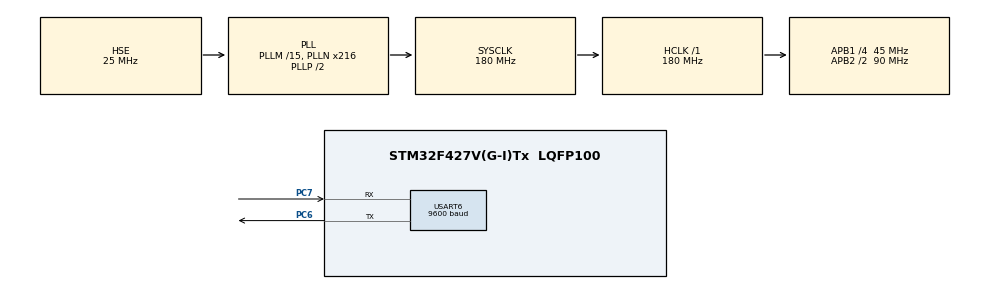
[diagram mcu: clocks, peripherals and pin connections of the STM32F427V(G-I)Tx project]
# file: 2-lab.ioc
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Mcu.Family=STM32F4
Mcu.Name=STM32F427V(G-I)Tx
Mcu.Package=LQFP100
NVIC.PriorityGroup=NVIC_PRIORITYGROUP_4
NVIC.USART6_IRQn=true\:0\:0\:false\:false\:true\:true\:true\:true
PA13.Mode=JTAG_5_pins
PA13.Signal=SYS_JTMS-SWDIO
PA14.Mode=JTAG_5_pins
PA14.Signal=SYS_JTCK-SWCLK
PA15.Mode=JTAG_5_pins
PA15.Signal=SYS_JTDI
PB3.Mode=JTAG_5_pins
PB3.Signal=SYS_JTDO-SWO
PB4.Mode=JTAG_5_pins
PB4.Signal=SYS_JTRST
PC6.Mode=Asynchronous
PC6.Signal=USART6_TX
PC7.Mode=Asynchronous
PC7.Signal=USART6_RX
PH0/OSC_IN.Mode=HSE-External-Oscillator
PH0/OSC_IN.Signal=RCC_OSC_IN
PH1/OSC_OUT.Mode=HSE-External-Oscillator
PH1/OSC_OUT.Signal=RCC_OSC_OUT
ProjectManager.HeapSize=0x200
ProjectManager.StackSize=0x400
ProjectManager.TargetToolchain=STM32CubeIDE
RCC.48MHZClocksFreq_Value=90000000
RCC.AHBFreq_Value=180000000
RCC.APB1CLKDivider=RCC_HCLK_DIV4
RCC.APB1Freq_Value=45000000
RCC.APB1TimFreq_Value=90000000
RCC.APB2CLKDivider=RCC_HCLK_DIV2
RCC.APB2Freq_Value=90000000
RCC.APB2TimFreq_Value=180000000
RCC.CortexFreq_Value=180000000
RCC.HCLKFreq_Value=180000000
RCC.HSE_VALUE=25000000
RCC.HSI_VALUE=16000000
RCC.LSE_VALUE=32768
RCC.PLLM=15
RCC.PLLN=216
RCC.PLLSourceVirtual=RCC_PLLSOURCE_HSE
RCC.SYSCLKFreq_VALUE=180000000
RCC.SYSCLKSource=RCC_SYSCLKSOURCE_PLLCLK
RCC.VCOOutputFreq_Value=360000000
USART6.BaudRate=9600
USART6.VirtualMode=VM_ASYNC
board=custom

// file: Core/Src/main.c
/* USER CODE BEGIN Header */
/**
  ******************************************************************************
  * @file           : main.c
  * @brief          : Main program body
  ******************************************************************************
  * @attention
  *
  * Copyright (c) 2024 STMicroelectronics.
  * All rights reserved.
  *
  * This software is licensed under terms that can be found in the LICENSE file
  * in the root directory of this software component.
  * If no LICENSE file comes with this software, it is provided AS-IS.
  *
  ******************************************************************************
  */
/* USER CODE END Header */
#include "main.h"
#include "usart.h"
#include "gpio.h"

/* USER CODE BEGIN Includes */
#include "stdio.h"
#include "stdbool.h"
#include "string.h"
/* USER CODE END Includes */

/* USER CODE BEGIN PTD */
typedef enum {
	DEFAULT = 0,
	PASS_CHANGE,
	CONFIRMATION
} InputMode;

typedef struct {
	bool is_pressed;
	bool signaled;
	uint32_t press_start_time;
} ButtonState;

#define BUF_SIZE 				1024

typedef struct RingBuffer {
	char data[BUF_SIZE];
	uint8_t head;
	uint8_t tail;
	bool is_empty;
} RingBuffer;
/* USER CODE END PTD */

/* USER CODE BEGIN PD */
#define BUTTON_PIN				GPIO_PIN_15
#define GREEN_LED_PIN			GPIO_PIN_13
#define YELLOW_LED_PIN			GPIO_PIN_14
#define RED_LED_PIN				GPIO_PIN_15
#define RESET_ALL_TIMEOUT_MS	1500
#define ENTER_ASCII				'\r'
#define ASCII_LATIN_CASE_DIFF	32
/* USER CODE END PD */

/* USER CODE BEGIN PV */
char newline[] = "\r\n";
char confirmation_message[] = "Confirm password change? 'y' for yes: ";
char interruptions_on_message[] = "Interruptions on";
char interruptions_off_message[] = "Interruptions off";

char last_received_char[2] = {'\0', '\0'};

char code[8] = "pass";
uint8_t code_ptr = 0;
uint8_t code_length = 4;
char new_code[8];
uint8_t new_code_ptr = 0;

uint8_t failed_attempts_cnt = 0;
uint32_t last_input_time = 0;
char cur_char = '\0';

ButtonState button_state = {.press_start_time = 0, .signaled = false, .is_pressed = false};

bool interruptions_enabled = false;

bool transmit_busy = false;
bool receive_busy = false;

RingBuffer receive_buffer;
RingBuffer transmit_buffer;

char buf_char[2] = {'\0', '\0'};

InputMode mode = DEFAULT;

void buf_init(RingBuffer *buf) {
	buf->head = 0;
	buf->tail = 0;
	buf->is_empty = true;
}

void buf_write(RingBuffer *buf, char *in) {
	uint32_t pmask = __get_PRIMASK();
	__disable_irq();

	uint64_t size = strlen(in);

	if (buf->head + size + 1 > BUF_SIZE)
		buf->head = 0;

	strcpy(&buf->data[buf->head], in);
	buf->head += size + 1;

	if (buf->head == BUF_SIZE)
		buf->head = 0;

	buf->is_empty = false;

	__set_PRIMASK(pmask);
}

bool buf_read(RingBuffer *buf, char *out) {
	uint32_t pmask = __get_PRIMASK();
	__disable_irq();

	if (buf->is_empty){
		__set_PRIMASK(pmask);
		return false;
	}

	uint64_t size = strlen(&buf->data[buf->tail]);

	strcpy(out, &buf->data[buf->tail]);
	buf->tail += size + 1;

	if (buf->tail == BUF_SIZE || buf->tail == '\0')
		buf->tail = 0;

	if (buf->tail == buf->head)
		buf->is_empty = true;

	__set_PRIMASK(pmask);
	return true;
}
/* USER CODE END PV */

void SystemClock_Config(void);

/* USER CODE BEGIN 0 */
extern void initialise_monitor_handles(void);

GPIO_PinState read_button(void) {
	return HAL_GPIO_ReadPin(GPIOC, BUTTON_PIN);
}

void enable_interruptions(void) {
	HAL_NVIC_EnableIRQ(USART6_IRQn);
	interruptions_enabled = true;
}

void disable_interruptions(void) {
	while (transmit_busy) ; // wait until everything from transmit_buffer is sent to the UART
	HAL_UART_AbortReceive(&huart6);
	HAL_NVIC_DisableIRQ(USART6_IRQn);
	interruptions_enabled = false;
}

void light_led(uint16_t led_pin, uint8_t blink_cnt, uint8_t time) {
	while (blink_cnt--) {
		HAL_GPIO_WritePin(GPIOD, led_pin, GPIO_PIN_SET);
		HAL_Delay(time);
		HAL_GPIO_WritePin(GPIOD, led_pin, GPIO_PIN_RESET);
		HAL_Delay(time);
	}
}

void uart_write(char *data) {
	uint16_t size = strlen(data);
	if (interruptions_enabled) {
		if (transmit_busy) {
			buf_write(&transmit_buffer, data);
		} else {
			transmit_busy = true;
			HAL_UART_Transmit_IT(&huart6, (uint8_t *) data, size);
		}
	} else HAL_UART_Transmit(&huart6, (uint8_t *) data, size, 100);
}

void uart_write_newline(void) {
	uart_write(newline);
}

void HAL_UART_TxCpltCallback(UART_HandleTypeDef *huart) {
	char buf[BUF_SIZE];
	if (buf_read(&transmit_buffer, buf))
		HAL_UART_Transmit_IT(&huart6, (uint8_t *) &buf, strlen(buf));
	else transmit_busy = false;
}

bool process_char(char *c) {
	if ('A' <= c[0] && c[0] <= 'Z') {
		c[0] += ASCII_LATIN_CASE_DIFF;
		return true;
	}
	if ('a' <= c[0] && c[0] <= 'z') {
		return true;
	}
	if (c[0] == ENTER_ASCII && PASS_CHANGE == mode) {
		return true;
	}
	if (c[0] == '+' && DEFAULT == mode) {
		return true;
	}
	c[0] = '\0';
	return false;
}

void uart_read_char(void) {
	if (interruptions_enabled) {
		if (receive_busy) return;
		receive_busy = true;
		HAL_UART_Receive_IT(&huart6, (uint8_t *) buf_char, sizeof(char));
		return;
	}
	HAL_StatusTypeDef status = HAL_UART_Receive(&huart6, (uint8_t *) buf_char, sizeof(char), 100);
	if (HAL_OK == status && process_char(buf_char)) {
		uart_write(buf_char);
		buf_write(&receive_buffer, buf_char);
	}
}

void HAL_UART_RxCpltCallback(UART_HandleTypeDef *huart) {
	receive_busy = false;
	if (process_char(buf_char)) {
		buf_write(&receive_buffer, buf_char);
		uart_write(buf_char);
	}
}

bool update_button_state(void) {
	if (button_state.is_pressed) {
		button_state.is_pressed = read_button() == GPIO_PIN_RESET;
		if (button_state.signaled) return false;
		if ((HAL_GetTick() - button_state.press_start_time) > 20) {
			button_state.signaled = true;
			return true;
		}
		return false;
	}
	if (read_button() == GPIO_PIN_RESET) {
		button_state.press_start_time = HAL_GetTick();
		button_state.is_pressed = true;
		button_state.signaled = false;
	}
	return false;
}

void set_mode(InputMode new_mode) {
	uart_write_newline();
	mode = new_mode;
	switch (mode) {
		case DEFAULT:
			code_ptr = 0;
			break;
	  case CONFIRMATION:
		  if (new_code_ptr == 0) {
			  set_mode(DEFAULT);
			  break;
		  }
		  uart_write(confirmation_message);
		  break;
	  default:
		  break;
	}
}
/* USER CODE END 0 */

int main(void)
{
  /* USER CODE BEGIN 1 */
	initialise_monitor_handles();
  /* USER CODE END 1 */

  /* MCU Configuration--------------------------------------------------------*/

  /* Reset of all peripherals, Initializes the Flash interface and the Systick. */
  HAL_Init();

  /* USER CODE BEGIN Init */
	GPIO_InitTypeDef GPIO_InitStruct = {0};

	/* GPIO Ports Clock Enable */
	__HAL_RCC_GPIOC_CLK_ENABLE();
	__HAL_RCC_GPIOH_CLK_ENABLE();
	__HAL_RCC_GPIOD_CLK_ENABLE();
	__HAL_RCC_GPIOA_CLK_ENABLE();
	__HAL_RCC_GPIOB_CLK_ENABLE();

	/*Configure GPIO pin Output Level */
	HAL_GPIO_WritePin(GPIOD, GPIO_PIN_13|GPIO_PIN_14|GPIO_PIN_15, GPIO_PIN_RESET);

	/*Configure GPIO pin : PC15 */
	GPIO_InitStruct.Pin = GPIO_PIN_15;
	GPIO_InitStruct.Mode = GPIO_MODE_INPUT;
	GPIO_InitStruct.Pull = GPIO_NOPULL;
	HAL_GPIO_Init(GPIOC, &GPIO_InitStruct);

	/*Configure GPIO pins : PD13 PD14 PD15 */
	GPIO_InitStruct.Pin = GPIO_PIN_13|GPIO_PIN_14|GPIO_PIN_15;
	GPIO_InitStruct.Mode = GPIO_MODE_OUTPUT_PP;
	GPIO_InitStruct.Pull = GPIO_NOPULL;
	GPIO_InitStruct.Speed = GPIO_SPEED_FREQ_LOW;
	HAL_GPIO_Init(GPIOD, &GPIO_InitStruct);
  /* USER CODE END Init */

  /* Configure the system clock */
  SystemClock_Config();

  /* Initialize all configured peripherals */
  MX_GPIO_Init();
  MX_USART6_UART_Init();

  /* Infinite loop */
  /* USER CODE BEGIN WHILE */

  disable_interruptions();
  uart_write(interruptions_off_message);
  uart_write_newline();

  buf_init(&receive_buffer);
  buf_init(&transmit_buffer);

  char tmp[2];
  while (1)
  {
	  if (update_button_state()) {
		  if (interruptions_enabled) {
			  disable_interruptions();
			  uart_write(interruptions_off_message);
			  uart_write_newline();
		  } else {
			  enable_interruptions();
			  uart_write(interruptions_on_message);
			  uart_write_newline();
		  }
	  }

	  if (DEFAULT == mode && code_ptr != 0 && HAL_GetTick() - last_input_time >= RESET_ALL_TIMEOUT_MS) {
		  code_ptr = 0;
		  failed_attempts_cnt = 0;
		  uart_write_newline();
		  light_led(RED_LED_PIN | GREEN_LED_PIN, 5, 25);
		  last_input_time = HAL_GetTick();
		  continue;
	  }

	  uart_read_char();

	  if (!buf_read(&receive_buffer, tmp))
		  continue;

	  last_input_time = HAL_GetTick();
	  cur_char = tmp[0];

	  switch (mode) {
	  	  case DEFAULT:
	  		  if (cur_char == '+') {
	  			  set_mode(PASS_CHANGE);
	  			  continue;
	  		  }

	  		  if (code[code_ptr++] == cur_char) {
	  			  light_led(YELLOW_LED_PIN, 1, 100);
	  			  if (code_ptr == code_length) {
	  				  uart_write_newline();
	  				  light_led(GREEN_LED_PIN, 3, 50);
	  				  code_ptr = 0;
	  				  failed_attempts_cnt = 0;
	  			  }
	  		  } else {
	  			  uart_write_newline();
	  			  light_led(RED_LED_PIN, 1, 100);
				  code_ptr = 0;
				  if (++failed_attempts_cnt == 3) {
					  failed_attempts_cnt = 0;
					  light_led(RED_LED_PIN, 3, 50);
				  }
	  		  }
	  		  continue;

	  	  case PASS_CHANGE:
	  		  if (cur_char == ENTER_ASCII) {
	  			  set_mode(CONFIRMATION);
	  			  continue;
	  		  }

	  		  new_code[new_code_ptr++] = cur_char;
	  		  if (new_code_ptr == 8) set_mode(CONFIRMATION);
	  		  continue;

	  	  case CONFIRMATION:
	  		  if (cur_char == 'y') {
	  			  code_length = new_code_ptr;
	  			  for (uint8_t i = 0; i < code_length; i++)
	  				  code[i] = new_code[i];
	  		  }
	  		  new_code_ptr = 0;
	  		  set_mode(DEFAULT);
	  		  continue;
	  }

    /* USER CODE END WHILE */

  }
}

void SystemClock_Config(void)
{
  RCC_OscInitTypeDef RCC_OscInitStruct = {0};
  RCC_ClkInitTypeDef RCC_ClkInitStruct = {0};

  /** Configure the main internal regulator output voltage
  */
  __HAL_RCC_PWR_CLK_ENABLE();
  __HAL_PWR_VOLTAGESCALING_CONFIG(PWR_REGULATOR_VOLTAGE_SCALE1);

  /** Initializes the RCC Oscillators according to the specified parameters
  * in the RCC_OscInitTypeDef structure.
  */
  RCC_OscInitStruct.OscillatorType = RCC_OSCILLATORTYPE_HSE;
  RCC_OscInitStruct.HSEState = RCC_HSE_ON;
  RCC_OscInitStruct.PLL.PLLState = RCC_PLL_ON;
  RCC_OscInitStruct.PLL.PLLSource = RCC_PLLSOURCE_HSE;
  RCC_OscInitStruct.PLL.PLLM = 15;
  RCC_OscInitStruct.PLL.PLLN = 216;
  RCC_OscInitStruct.PLL.PLLP = RCC_PLLP_DIV2;
  RCC_OscInitStruct.PLL.PLLQ = 4;
  if (HAL_RCC_OscConfig(&RCC_OscInitStruct) != HAL_OK)
  {
    Error_Handler();
  }

  /** Activate the Over-Drive mode
  */
  if (HAL_PWREx_EnableOverDrive() != HAL_OK)
  {
    Error_Handler();
  }

  /** Initializes the CPU, AHB and APB buses clocks
  */
  RCC_ClkInitStruct.ClockType = RCC_CLOCKTYPE_HCLK|RCC_CLOCKTYPE_SYSCLK
                              |RCC_CLOCKTYPE_PCLK1|RCC_CLOCKTYPE_PCLK2;
  RCC_ClkInitStruct.SYSCLKSource = RCC_SYSCLKSOURCE_PLLCLK;
  RCC_ClkInitStruct.AHBCLKDivider = RCC_SYSCLK_DIV1;
  RCC_ClkInitStruct.APB1CLKDivider = RCC_HCLK_DIV4;
  RCC_ClkInitStruct.APB2CLKDivider = RCC_HCLK_DIV2;

  if (HAL_RCC_ClockConfig(&RCC_ClkInitStruct, FLASH_LATENCY_5) != HAL_OK)
  {
    Error_Handler();
  }
}

void Error_Handler(void)
{
  __disable_irq();
  while (1)
  {
  }
}
